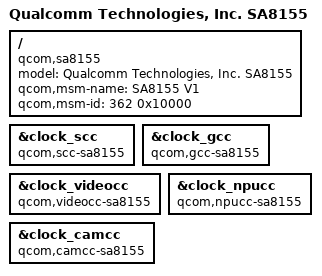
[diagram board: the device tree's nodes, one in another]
/* Copyright (c) 2018-2019, The Linux Foundation. All rights reserved.
 *
 * This program is free software; you can redistribute it and/or modify
 * it under the terms of the GNU General Public License version 2 and
 * only version 2 as published by the Free Software Foundation.
 *
 * This program is distributed in the hope that it will be useful,
 * but WITHOUT ANY WARRANTY; without even the implied warranty of
 * MERCHANTABILITY or FITNESS FOR A PARTICULAR PURPOSE.  See the
 * GNU General Public License for more details.
 */

#include "sm8150.dtsi"
#include "sa8155.dtsi"

/ {
	model = "Qualcomm Technologies, Inc. SA8155";
	compatible = "qcom,sa8155";
	qcom,msm-name = "SA8155 V1";
	qcom,msm-id = <362 0x10000>;
};

&clock_scc {
	compatible = "qcom,scc-sa8155";
};

&clock_gcc {
	compatible = "qcom,gcc-sa8155", "syscon";
};

&clock_videocc {
	compatible = "qcom,videocc-sa8155", "syscon";
};

&clock_npucc {
	compatible = "qcom,npucc-sa8155", "syscon";
};

&clock_camcc {
	compatible = "qcom,camcc-sa8155", "syscon";
};
